# STM32N655 register map
File version: 1.0
CPU: CM55 r0p1, little endian, no MPU, FPU, vendor SysTick, 8 interrupt priority bits
Registers are 32-bit, read-write, reset 0x0 unless marked. A register's access mark holds for its fields unless they carry their own. Offsets are from the block's base; [hi:lo] are bit positions; {n}, {i} and the like mark numbered series.

## CRC — Cyclic redundancy check calculation unit
Base 0x46024C00
Same registers: CRC_S 0x56024C00
0x00 DR reset 0xFFFFFFFF — CRC data register
  [31:0] DR — Data register bits
0x04 IDR — CRC independent data register
  [31:0] IDR — General-purpose 32-bit data register bits
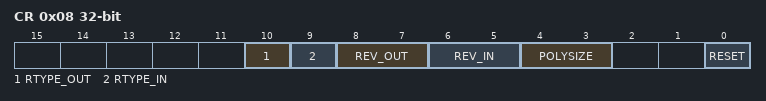
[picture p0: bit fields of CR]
0x08 CR — CRC control register
  [10] RTYPE_OUT — Reverse type output
  [9] RTYPE_IN — Reverse type input
  [8:7] REV_OUT — Reverse output data
  [6:5] REV_IN — Reverse input data
  [4:3] POLYSIZE — Polynomial size
  [0] RESET — RESET bit
0x10 INIT reset 0xFFFFFFFF — CRC initial value
  [31:0] CRC_INIT — Programmable initial CRC value
0x14 POL reset 0x4C11DB7 — CRC polynomial
  [31:0] POL — Programmable polynomial

## CRYP — Cryptographic processor
Base 0x44020800
Same registers: CRYP_S 0x54020800
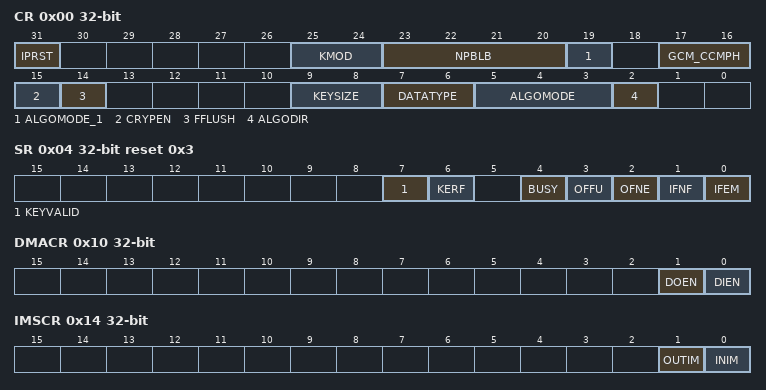
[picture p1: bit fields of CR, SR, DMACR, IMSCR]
0x00 CR — CRYP control register
  [31] IPRST — CRYP peripheral software reset
  [25:24] KMOD — Key mode selection
  [23:20] NPBLB — Number of padding bytes in last block
  [19] ALGOMODE_1 — ALGOMODE[3]
  [17:16] GCM_CCMPH — GCM or CCM phase selection
  [15] CRYPEN — CRYP enable
  [14] FFLUSH — FIFO flush
  [9:8] KEYSIZE — Key size selection
  [7:6] DATATYPE
  [5:3] ALGOMODE — ALGOMODE[2:0]: Algorithm mode
  [2] ALGODIR — Algorithm direction
0x04 SR ro reset 0x3 — CRYP status register
  [7] KEYVALID — Key valid flag
  [6] KERF — Key error flag
  [4] BUSY — Busy bit
  [3] OFFU — Output FIFO full flag
  [2] OFNE — Output FIFO not empty flag
  [1] IFNF — Input FIFO not full flag
  [0] IFEM — Input FIFO empty flag
0x08 DINR — CRYP data input register
  [31:0] DIN — Data input
0x0C DOUTR ro — CRYP data output register
  [31:0] DOUT — Data output
0x10 DMACR — CRYP DMA control register
  [1] DOEN — DMA output enable
  [0] DIEN — DMA input enable
0x14 IMSCR — CRYP interrupt mask set/clear register
  [1] OUTIM — Output FIFO service interrupt mask
  [0] INIM — Input FIFO service interrupt mask
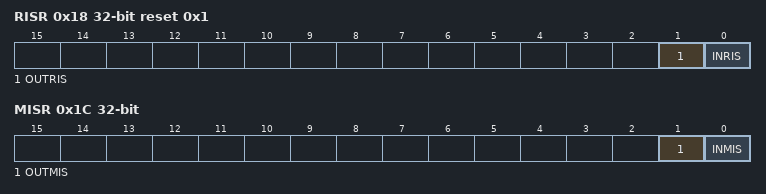
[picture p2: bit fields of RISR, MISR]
0x18 RISR ro reset 0x1 — CRYP raw interrupt status register
  [1] OUTRIS — Output FIFO service raw interrupt status
  [0] INRIS — Input FIFO service raw interrupt status
0x1C MISR ro — CRYP masked interrupt status register
  [1] OUTMIS — Output FIFO service masked interrupt status
  [0] INMIS — Input FIFO service masked interrupt status
{0x20+8i} K{i}LR wo (i=0..3) — CRYP key register {i}L
  [31:0] K — Key bit x
{0x24+8i} K{i}RR wo (i=0..3) — CRYP key register {i}R
  [31:0] K — Key bit x
0x40 IV0LR — CRYP initialization vector register 0L
  [31:0] IVI — Initialization vector bit x
0x44 IV0RR — CRYP initialization vector register 0R
  [31:0] IVI — Initialization vector bit x
0x48 IV1LR — CRYP initialization vector register 1L
  [31:0] IVI — Initialization vector bit x
0x4C IV1RR — CRYP initialization vector register 1R
  [31:0] IVI — Initialization vector bit x
{0x50+4i} CSGCMCCM{i}R (i=0..7) — CRYP context swap GCM-CCM registers
  [31:0] CSGCMCCM — Context swap for GCM/GMAC and CCM modes
{0x70+4i} CSGCM{i}R (i=0..7) — CRYP context swap GCM registers
  [31:0] CSGCM — Context swap for GCM/GMAC modes

## DBGMCU — Microcontroller debug unit
Base 0x44001000
Same registers: DBGMCU_S 0x54001000
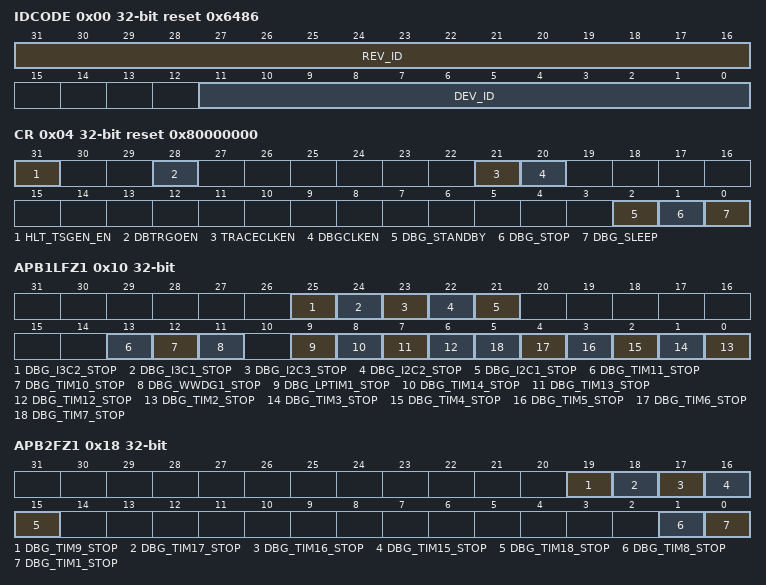
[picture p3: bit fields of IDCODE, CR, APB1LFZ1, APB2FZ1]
0x00 IDCODE ro reset 0x6486 (reset mask 0xFFFF) — DBGMCU identity code register
  [31:16] REV_ID — Revision
  [11:0] DEV_ID — Device ID
0x04 CR reset 0x80000000 — DBGMCU configuration register
  [31] HLT_TSGEN_EN — TSGEN halt enable
  [28] DBTRGOEN — DBTRGIO connection control
  [21] TRACECLKEN — TPIU export clock enable through software
  [20] DBGCLKEN — Debug clock enable through software
  [2] DBG_STANDBY — Allow debug in Standby mode
  [1] DBG_STOP — Allow debug in Stop mode
  [0] DBG_SLEEP — Allow debug in Sleep mode
0x10 APB1LFZ1 — DBGMCU APB1L peripheral freeze register
  [25] DBG_I3C2_STOP — I3C2 SMBUS timeout stop in debug
  [24] DBG_I3C1_STOP — I3C1 SMBUS timeout stop in debug
  [23] DBG_I2C3_STOP — I2C3 SMBUS timeout stop in debug
  [22] DBG_I2C2_STOP — I2C2 SMBUS timeout stop in debug
  [21] DBG_I2C1_STOP — I2C1 SMBUS timeout stop in debug
  [13] DBG_TIM11_STOP — TIM11 stop in debug
  [12] DBG_TIM10_STOP — TIM10 stop in debug
  [11] DBG_WWDG1_STOP — WWDG1 stop in debug
  [9] DBG_LPTIM1_STOP — LPTIM1 stop in debug
  [8] DBG_TIM14_STOP — TIM14 stop in debug
  [7] DBG_TIM13_STOP — TIM13 stop in debug
  [6] DBG_TIM12_STOP — TIM12 stop in debug
  [n-2] DBG_TIM{n}_STOP (n=2..7) — TIM{n} stop in debug
0x14 APB1HFZ1 — DBGMCU APB1H peripheral freeze register
  [8] DBG_FDCAN_STOP — FDCAN stop in debug
0x18 APB2FZ1 — DBGMCU APB2 peripheral freeze register
  [19] DBG_TIM9_STOP — TIM9 stop in debug
  [18] DBG_TIM17_STOP — TIM17 stop in debug
  [17] DBG_TIM16_STOP — TIM16 stop in debug
  [16] DBG_TIM15_STOP — TIM15 stop in debug
  [15] DBG_TIM18_STOP — TIM18 stop in debug
  [1] DBG_TIM8_STOP — TIM8 stop in debug
  [0] DBG_TIM1_STOP — TIM1 stop in debug
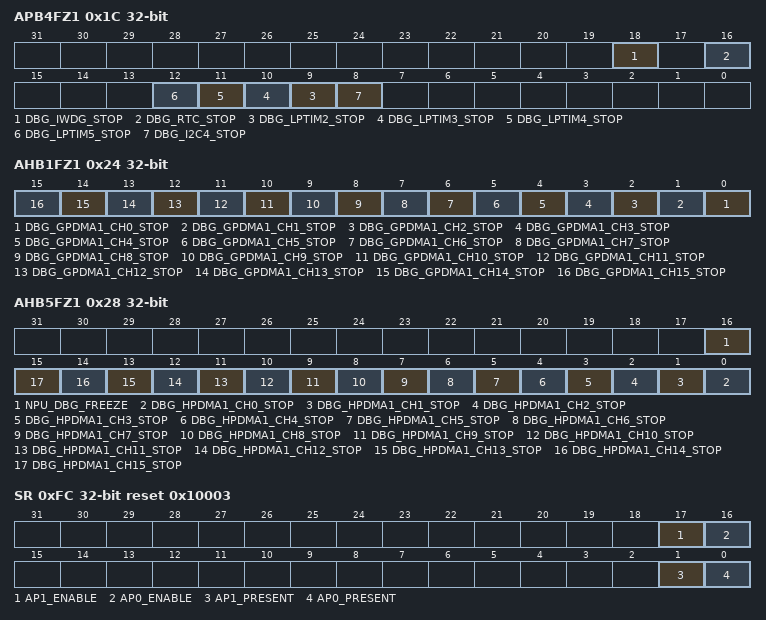
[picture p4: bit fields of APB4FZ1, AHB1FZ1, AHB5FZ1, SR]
0x1C APB4FZ1 — DBGMCU APB4 peripheral freeze register
  [18] DBG_IWDG_STOP — WWDG stop in debug
  [16] DBG_RTC_STOP — RTC clock is suspended in debug
  [n+7] DBG_LPTIM{n}_STOP (n=2..5) — LPTIM{n} stop in debug
  [8] DBG_I2C4_STOP — I2C4 stop in debug
0x20 APB5FZ1 — DBGMCU APB5 peripheral freeze register
  [4] DBG_GFXTIM_STOP — GFXTIM stop in debug
0x24 AHB1FZ1 — DBGMCU AHB1 peripheral freeze register
  [n] DBG_GPDMA1_CH{n}_STOP (n=0..15) — GPDMA1_CHn suspend in debug
0x28 AHB5FZ1 — DBGMCU AHB5 peripheral freeze register
  [16] NPU_DBG_FREEZE — NPU stop in debug mode
  [n] DBG_HPDMA1_CH{n}_STOP (n=0..15) — HPDMA3_CHn suspend in debug
0xFC SR ro reset 0x10003 — DBGMCU status register
  [17] AP1_ENABLE — Access point 1 enable
  [16] AP0_ENABLE — Access point 0 enable
  [1] AP1_PRESENT — Access point 1 presence
  [0] AP0_PRESENT — Access point 0 presence
0x100 DBG_AUTH_HOST — DBGMCU host authentication register
  [31:0] MESSAGE — Mailbox between debugger and processor
0x104 DBG_AUTH_DEV — DBGMCU device authentication register
  [31:0] MESSAGE — Mailbox between debugger and processor
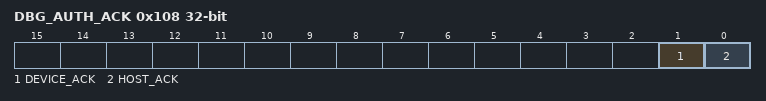
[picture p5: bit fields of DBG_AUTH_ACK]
0x108 DBG_AUTH_ACK ro — DBGMCU message read acknowledge authentication register
  [1] DEVICE_ACK — Access status to DBG_AUTH_DEV register
  [0] HOST_ACK — Access status to DBG_AUTH_HOST register
